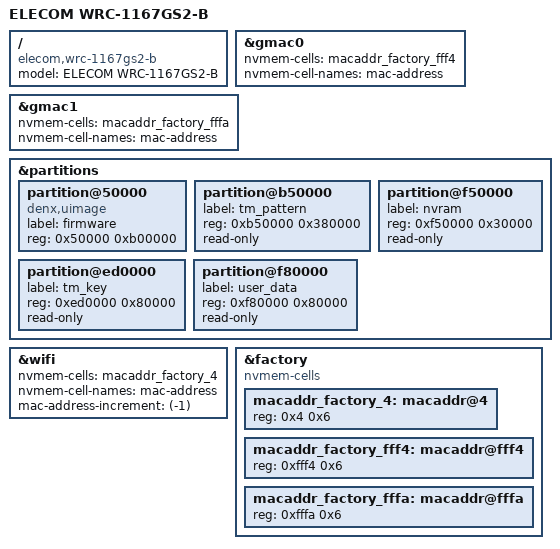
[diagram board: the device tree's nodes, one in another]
// SPDX-License-Identifier: GPL-2.0-or-later OR MIT

#include "mt7621_elecom_wrc-gs-1pci.dtsi"

/ {
	compatible = "elecom,wrc-1167gs2-b", "mediatek,mt7621-soc";
	model = "ELECOM WRC-1167GS2-B";
};

&gmac0 {
	nvmem-cells = <&macaddr_factory_fff4>;
	nvmem-cell-names = "mac-address";
};

&gmac1 {
	nvmem-cells = <&macaddr_factory_fffa>;
	nvmem-cell-names = "mac-address";
};

&partitions {
	partition@50000 {
		compatible = "denx,uimage";
		label = "firmware";
		reg = <0x50000 0xb00000>;
	};

	partition@b50000 {
		label = "tm_pattern";
		reg = <0xb50000 0x380000>;
		read-only;
	};

	partition@ed0000 {
		label = "tm_key";
		reg = <0xed0000 0x80000>;
		read-only;
	};

	partition@f50000 {
		label = "nvram";
		reg = <0xf50000 0x30000>;
		read-only;
	};

	partition@f80000 {
		label = "user_data";
		reg = <0xf80000 0x80000>;
		read-only;
	};
};

&wifi {
	nvmem-cells = <&macaddr_factory_4>;
	nvmem-cell-names = "mac-address";
	mac-address-increment = <(-1)>;
};

&factory {
	compatible = "nvmem-cells";
	#address-cells = <1>;
	#size-cells = <1>;

	macaddr_factory_4: macaddr@4 {
		reg = <0x4 0x6>;
	};

	macaddr_factory_fff4: macaddr@fff4 {
		reg = <0xfff4 0x6>;
	};

	macaddr_factory_fffa: macaddr@fffa {
		reg = <0xfffa 0x6>;
	};
};
